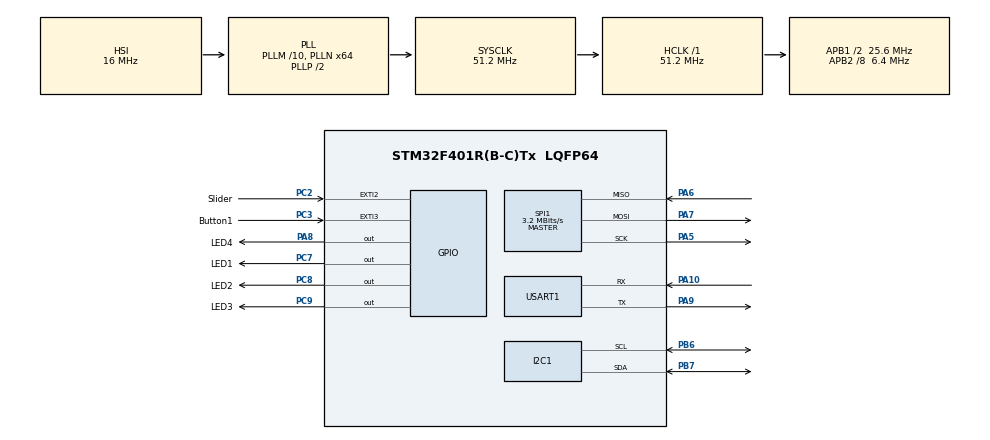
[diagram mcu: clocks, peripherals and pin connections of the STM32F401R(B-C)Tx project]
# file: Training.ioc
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Mcu.Family=STM32F4
Mcu.Name=STM32F401R(B-C)Tx
Mcu.Package=LQFP64
NVIC.EXTI2_IRQn=true\:0\:0\:false\:false\:true\:true\:true\:true
NVIC.EXTI3_IRQn=true\:0\:0\:false\:false\:true\:true\:true\:true
NVIC.PriorityGroup=NVIC_PRIORITYGROUP_4
PA10.Mode=Asynchronous
PA10.Signal=USART1_RX
PA5.Mode=Full_Duplex_Master
PA5.Signal=SPI1_SCK
PA6.Mode=Full_Duplex_Master
PA6.Signal=SPI1_MISO
PA7.Mode=Full_Duplex_Master
PA7.Signal=SPI1_MOSI
PA8.GPIO_Label=LED4
PA8.GPIO_PuPd=GPIO_PULLUP
PA8.PinState=GPIO_PIN_SET
PA8.Signal=GPIO_Output
PA9.Mode=Asynchronous
PA9.Signal=USART1_TX
PB6.Mode=I2C
PB6.Signal=I2C1_SCL
PB7.Mode=I2C
PB7.Signal=I2C1_SDA
PC2.GPIO_Label=Slider
PC2.GPIO_ModeDefaultEXTI=GPIO_MODE_IT_RISING_FALLING
PC2.GPIO_PuPd=GPIO_PULLUP
PC2.Signal=GPXTI2
PC3.GPIO_Label=Button1
PC3.GPIO_ModeDefaultEXTI=GPIO_MODE_IT_RISING_FALLING
PC3.GPIO_PuPd=GPIO_PULLUP
PC3.Signal=GPXTI3
PC7.GPIO_Label=LED1
PC7.GPIO_PuPd=GPIO_PULLUP
PC7.PinState=GPIO_PIN_SET
PC7.Signal=GPIO_Output
PC8.GPIO_Label=LED2
PC8.GPIO_PuPd=GPIO_PULLUP
PC8.PinState=GPIO_PIN_SET
PC8.Signal=GPIO_Output
PC9.GPIO_Label=LED3
PC9.GPIO_PuPd=GPIO_PULLUP
PC9.PinState=GPIO_PIN_SET
PC9.Signal=GPIO_Output
ProjectManager.HeapSize=0x200
ProjectManager.StackSize=0x400
ProjectManager.TargetToolchain=STM32CubeIDE
RCC.48MHZClocksFreq_Value=25600000
RCC.AHBFreq_Value=51200000
RCC.APB1CLKDivider=RCC_HCLK_DIV2
RCC.APB1Freq_Value=25600000
RCC.APB1TimFreq_Value=51200000
RCC.APB2CLKDivider=RCC_HCLK_DIV8
RCC.APB2Freq_Value=6400000
RCC.APB2TimFreq_Value=12800000
RCC.CortexFreq_Value=51200000
RCC.HCLKFreq_Value=51200000
RCC.HSE_VALUE=25000000
RCC.HSI_VALUE=16000000
RCC.LSE_VALUE=32768
RCC.PLLM=10
RCC.PLLN=64
RCC.SYSCLKFreq_VALUE=51200000
RCC.SYSCLKSource=RCC_SYSCLKSOURCE_PLLCLK
RCC.VCOOutputFreq_Value=102400000
SPI1.BaudRatePrescaler=SPI_BAUDRATEPRESCALER_2
SPI1.CalculateBaudRate=3.2 MBits/s
SPI1.Direction=SPI_DIRECTION_2LINES
SPI1.Mode=SPI_MODE_MASTER
SPI1.VirtualType=VM_MASTER
USART1.VirtualMode=VM_ASYNC
board=custom

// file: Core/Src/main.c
/* USER CODE BEGIN Header */
/**
  ******************************************************************************
  * @file           : main.c
  * @brief          : Main program body
  ******************************************************************************
  * @attention
  *
  * Copyright (c) 2025 STMicroelectronics.
  * All rights reserved.
  *
  * This software is licensed under terms that can be found in the LICENSE file
  * in the root directory of this software component.
  * If no LICENSE file comes with this software, it is provided AS-IS.
  *
  ******************************************************************************
  */
/* USER CODE END Header */
#include "main.h"
#include "i2c.h"
#include "spi.h"
#include "usart.h"
#include "gpio.h"

/* USER CODE BEGIN Includes */

#include "../../Project/Manager/Manager.h"

/* USER CODE END Includes */

/* USER CODE BEGIN PV */
#ifdef __GNUC__
    #define PUTCHAR_PROTOTYPE int __io_putchar(int ch)
#else
    #define PUTCHAR_PROTOTYPE int fputc(int ch, FILE *f)
#endif

extern UART_HandleTypeDef  huart1;

PUTCHAR_PROTOTYPE
{
    HAL_UART_Transmit(&huart1, (uint8_t *)&ch, 1, HAL_MAX_DELAY);
    return ch;
}
/* USER CODE END PV */

void SystemClock_Config(void);

int main(void)
{

  /* MCU Configuration--------------------------------------------------------*/

  /* Reset of all peripherals, Initializes the Flash interface and the Systick. */
  HAL_Init();

  /* Configure the system clock */
  SystemClock_Config();

  /* Initialize all configured peripherals */
  MX_GPIO_Init();
  MX_I2C1_Init();
  MX_USART1_UART_Init();
  MX_SPI1_Init();
  /* USER CODE BEGIN 2 */

  Manager_Initialize();

  /* USER CODE END 2 */

  /* Infinite loop */
  while (1)
    {

    /* USER CODE BEGIN 3 */
          Manager_Loop();
    }
  /* USER CODE END 3 */
}

void SystemClock_Config(void)
{
  RCC_OscInitTypeDef RCC_OscInitStruct = {0};
  RCC_ClkInitTypeDef RCC_ClkInitStruct = {0};

  /** Configure the main internal regulator output voltage
  */
  __HAL_RCC_PWR_CLK_ENABLE();
  __HAL_PWR_VOLTAGESCALING_CONFIG(PWR_REGULATOR_VOLTAGE_SCALE2);

  /** Initializes the RCC Oscillators according to the specified parameters
  * in the RCC_OscInitTypeDef structure.
  */
  RCC_OscInitStruct.OscillatorType = RCC_OSCILLATORTYPE_HSI;
  RCC_OscInitStruct.HSIState = RCC_HSI_ON;
  RCC_OscInitStruct.HSICalibrationValue = RCC_HSICALIBRATION_DEFAULT;
  RCC_OscInitStruct.PLL.PLLState = RCC_PLL_ON;
  RCC_OscInitStruct.PLL.PLLSource = RCC_PLLSOURCE_HSI;
  RCC_OscInitStruct.PLL.PLLM = 10;
  RCC_OscInitStruct.PLL.PLLN = 64;
  RCC_OscInitStruct.PLL.PLLP = RCC_PLLP_DIV2;
  RCC_OscInitStruct.PLL.PLLQ = 4;
  if (HAL_RCC_OscConfig(&RCC_OscInitStruct) != HAL_OK)
  {
    Error_Handler();
  }

  /** Initializes the CPU, AHB and APB buses clocks
  */
  RCC_ClkInitStruct.ClockType = RCC_CLOCKTYPE_HCLK|RCC_CLOCKTYPE_SYSCLK
                              |RCC_CLOCKTYPE_PCLK1|RCC_CLOCKTYPE_PCLK2;
  RCC_ClkInitStruct.SYSCLKSource = RCC_SYSCLKSOURCE_PLLCLK;
  RCC_ClkInitStruct.AHBCLKDivider = RCC_SYSCLK_DIV1;
  RCC_ClkInitStruct.APB1CLKDivider = RCC_HCLK_DIV2;
  RCC_ClkInitStruct.APB2CLKDivider = RCC_HCLK_DIV8;

  if (HAL_RCC_ClockConfig(&RCC_ClkInitStruct, FLASH_LATENCY_1) != HAL_OK)
  {
    Error_Handler();
  }
}

void Error_Handler(void)
{
  __disable_irq();
  while (1)
  {
  }
}
